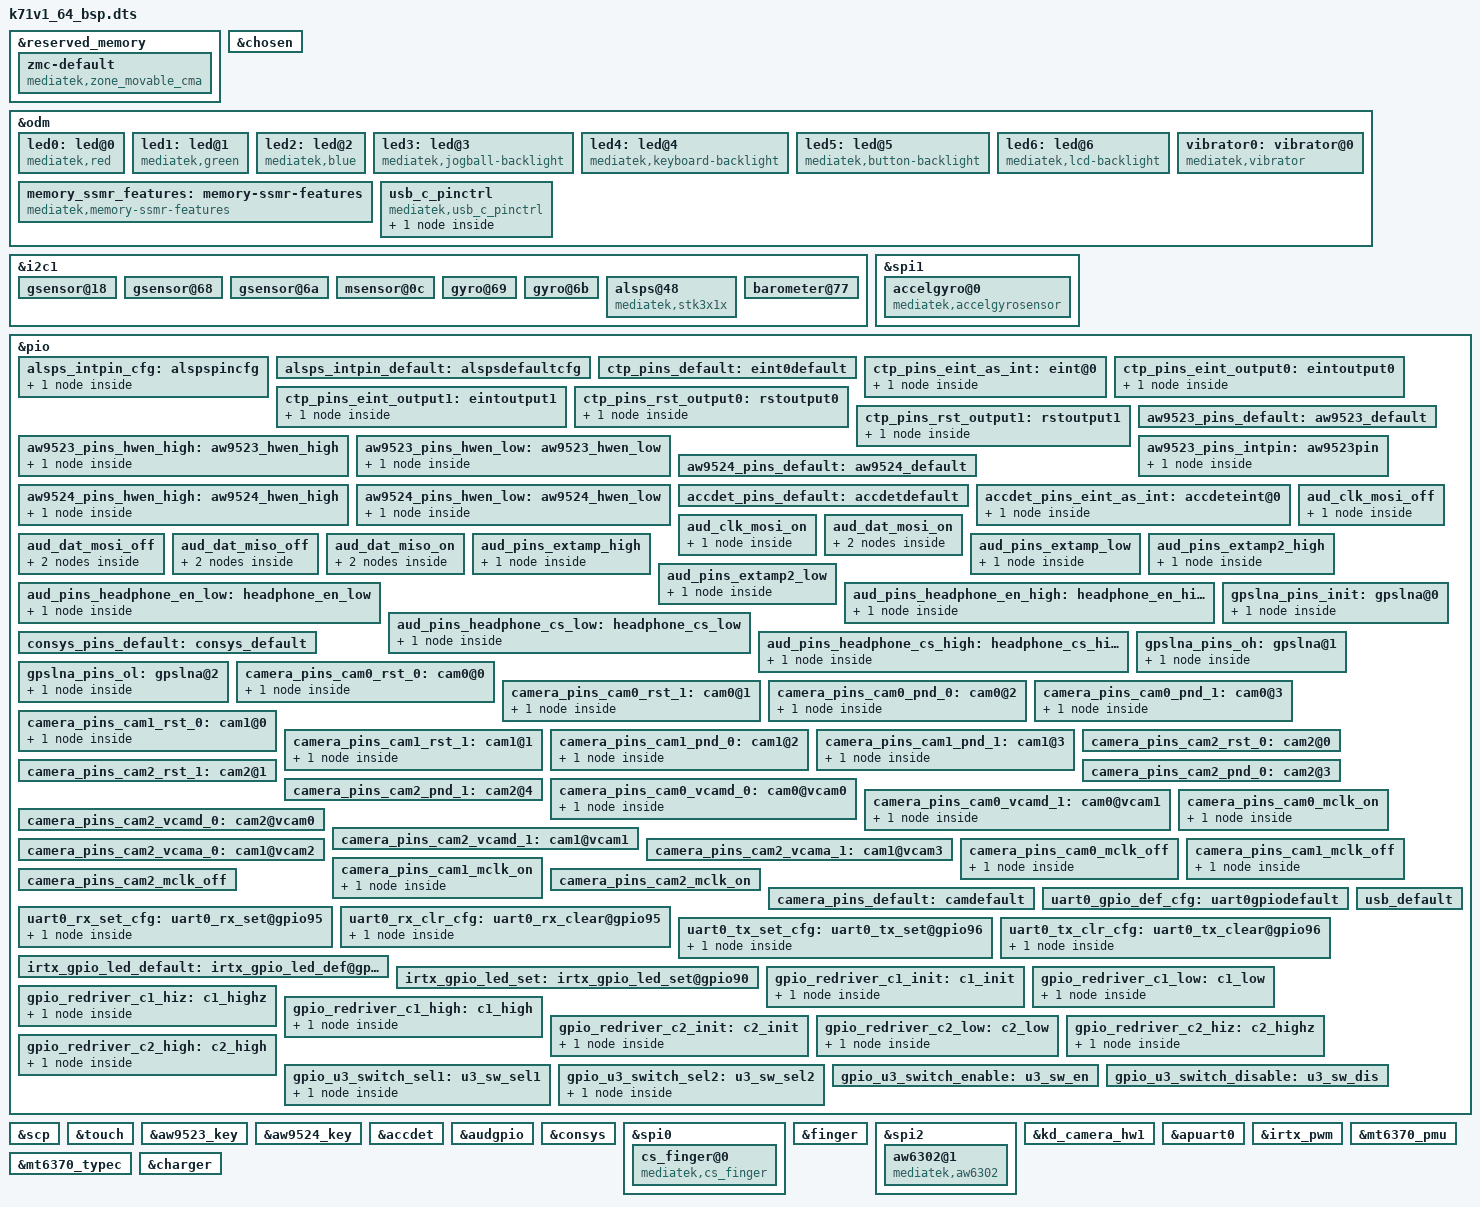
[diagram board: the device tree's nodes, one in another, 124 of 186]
/dts-v1/;
/plugin/;
#include <dt-bindings/interrupt-controller/irq.h>
#include <dt-bindings/interrupt-controller/arm-gic.h>
#include <dt-bindings/pinctrl/mt6771-pinfunc.h>

&reserved_memory {
	#address-cells = <2>;
	#size-cells = <2>;
	ranges;

	zmc-default {
		compatible = "mediatek,zone_movable_cma";
		size = <0 0xffc00000>;
		alignment = <0 0x10000000>;
		alloc-ranges = <0 0xc0000000 1 0x00000000>;
	};
};

/* chosen */
&chosen {
	/* fpga may has no lk, we need to specify display info here */
	/* fb buffer is reserved using this dts by memory node above */

	atag,videolfb-fb_base_l = <0x5e605000>;
	atag,videolfb-fb_base_h = <0x0>;
	atag,videolfb-islcmfound = <1>;
	atag,videolfb-islcm_inited = <0>;
	atag,videolfb-fps= <6000>;
	atag,videolfb-vramSize= <0x017bb000>;
	atag,videolfb-lcmname= "nt35595_fhd_dsi_cmd_truly_nt50358_drv";
};

&odm {
	led0:led@0 {
		compatible = "mediatek,red";
		led_mode = <0>;
		data = <1>;
		pwm_config = <0 0 0 0 0>;
	};
	led1:led@1 {
		compatible = "mediatek,green";
		led_mode = <0>;
		data = <1>;
		pwm_config = <0 0 0 0 0>;
	};
	led2:led@2 {
		compatible = "mediatek,blue";
		led_mode = <0>;
		data = <1>;
		pwm_config = <0 0 0 0 0>;
	};
	led3:led@3 {
		compatible = "mediatek,jogball-backlight";
		led_mode = <0>;
		data = <1>;
		pwm_config = <0 0 0 0 0>;
	};
	led4:led@4 {
		compatible = "mediatek,keyboard-backlight";
		led_mode = <0>;
		data = <1>;
		pwm_config = <0 0 0 0 0>;
	};
	led5:led@5 {
		compatible = "mediatek,button-backlight";
		led_mode = <0>;
		data = <1>;
		pwm_config = <0 0 0 0 0>;
	};
	led6:led@6 {
		compatible = "mediatek,lcd-backlight";
		led_mode = <5>;
		data = <1>;
		pwm_config = <0 1 0 0 0>;
	};
	vibrator0:vibrator@0 {
		compatible = "mediatek,vibrator";
		vib_timer = <25>;
		vib_limit = <9>;
		vib_vol= <9>;
	};
	memory_ssmr_features: memory-ssmr-features {
		compatible = "mediatek,memory-ssmr-features";
		svp-size = <0 0>;
		iris-recognition-size = <0 0>;
		2d_fr-size = <0 0>;
		tui-size = <0 0>;
		wfd-size = <0 0>;
		prot-sharedmem-size = <0 0>;
	};
	usb_c_pinctrl:usb_c_pinctrl {
		compatible = "mediatek,usb_c_pinctrl";
	};
};

&i2c1 {
/*  start sensor */
	gsensor@18 {
		/**STK8BA53**/
		i2c_num	= <1>;
		direction = <5>;
		power_id = <0xffff>;
		power_vol = <0>;
		firlen = <1>;
		is_batch_supported = <0>;
	};
	gsensor@68 {
		/**bmi160**/
		i2c_num	= <1>;
		direction = <5>;
		power_id = <0xffff>;
		power_vol = <0>;
		firlen = <16>;
		is_batch_supported = <1>;
	};
	gsensor@6a {
		/**lsm6ds3hg**/
		i2c_num	= <1>;
		direction = <4>;
		power_id = <0xffff>;
		power_vol = <0>;
		firlen = <16>;
		is_batch_supported = <1>;
	};
	msensor@0c {
		i2c_num = <1>;
		i2c_addr = <0x0c 0 0 0>;
		direction = <2>;
		power_id = <0xffff>;
		power_vol = <0>;
		is_batch_supported = <0>;
	};

	gyro@69 {
		i2c_num = <1>;
		i2c_addr = <0x69 0 0 0>;
		direction = <5>;
		power_id = <0xffff>;
		power_vol = <0>;
		firlen = <0>;
		is_batch_supported = <0>;
	};
	gyro@6b {
		i2c_num = <1>;
		i2c_addr = <0x6B 0 0 0>;
		direction = <4>;
		power_id = <0xffff>;
		power_vol = <0>;
		firlen = <0>;
		is_batch_supported = <0>;
	};
	alsps@48 {
		compatible = "mediatek,stk3x1x";
		pinctrl-names = "pin_default", "pin_cfg";
		pinctrl-0 = <&alsps_intpin_default>;
		pinctrl-1 = <&alsps_intpin_cfg>;
		status = "okay";
		/* customization */
		i2c_num = <1>;
		i2c_addr = <0x48 0 0 0>;
		polling_mode_ps = <0>;
		polling_mode_als = <1>;
		/*power_id = <0xffff>;*/
		/*power_vol = <0>;*/
		als_level  = <10  20 36 59 80 120 180 260 450 845 1136 1545 2364 4655 6982>;
		als_value  = <0 10 40 65 90 145 225 300 550 930 1250 1700 2600 5120 7680 10240>;
		state_val = <0x0>;              /* disable all */
		psctrl_val = <0x31>;            /* ps_persistance=4, ps_gain=64X, PS_IT=0.37ms */
		alsctrl_val = <0x38>;           /* als_persistance=1, als_gain=64X, ALS_IT=50ms */
		ledctrl_val = <0xFF>;   /* 100mA IRDR, 64/64 LED duty */
		wait_val = <0x7>;               /* 50 ms */
		ps_high_thd_val = <1700>;
		ps_low_thd_val = <1500>;
		ps_threshold_high		=  <30>;
		ps_threshold_low		=  <21>;
		is_batch_supported_ps = <0>;
		is_batch_supported_als = <0>;
	};

	barometer@77 {
		i2c_num = <1>;
		i2c_addr = <0x77 0 0 0>;
		direction = <0>;
		power_id = <0xffff>;
		power_vol = <0>;
		firlen = <32>;
		is_batch_supported = <0>;
	};
/* end sensor */
};

&spi1 {
       accelgyro@0 {
               /**bmi160**/
               compatible = "mediatek,accelgyrosensor";
		reg = <0>;
		spi-max-frequency = <8000000>;
		netlink-event = <30>;
		status = "okay";
               direction = <4>;
               power_id = <0xffff>;
               power_vol = <0>;
               firlen = <16>;
               is_batch_supported = <0>;
       };
};

/* sensor gpio standization */
&pio {
	alsps_intpin_cfg: alspspincfg {

		pins_cmd_dat {
			pins = <PINMUX_GPIO6__FUNC_GPIO6>;
			slew-rate = <0>;
			bias-pull-up = <00>;
		};
	};

	alsps_intpin_default: alspsdefaultcfg {

	};
};
/* sensor end */

&scp {
	core_1 = "enable";
	scp_sramSize = <0x00080000>;     /* scp_A_sram_size */
};

/* TOUCH start */
&touch {
	tpd-resolution = <1080 1920>;
	use-tpd-button = <0>;
	tpd-key-num = <3>;
	tpd-key-local= <139 172 158 0>;
	tpd-key-dim-local = <90 883 100 40 230 883 100 40 370 883 100 40 0 0 0 0>;
	tpd-max-touch-num = <5>;
	tpd-filter-enable = <1>;
	tpd-filter-pixel-density = <146>;
	tpd-filter-custom-prameters = <0 0 0 0 0 0 0 0 0 0 0 0>;
	tpd-filter-custom-speed = <0 0 0>;
	pinctrl-names = "default", "state_eint_as_int", "state_eint_output0", "state_eint_output1",
		"state_rst_output0", "state_rst_output1";
	pinctrl-0 = <&ctp_pins_default>;
	pinctrl-1 = <&ctp_pins_eint_as_int>;
	pinctrl-2 = <&ctp_pins_eint_output0>;
	pinctrl-3 = <&ctp_pins_eint_output1>;
	pinctrl-4 = <&ctp_pins_rst_output0>;
	pinctrl-5 = <&ctp_pins_rst_output1>;
	status = "okay";
};
&pio {
	ctp_pins_default: eint0default {
	};
	ctp_pins_eint_as_int: eint@0 {
		pins_cmd_dat {
			pins = <PINMUX_GPIO9__FUNC_GPIO9>;
			slew-rate = <0>;
			bias-disable;
		};
	};
	ctp_pins_eint_output0: eintoutput0 {
		pins_cmd_dat {
			pins = <PINMUX_GPIO9__FUNC_GPIO9>;
			slew-rate = <1>;
			output-low;
		};
	};
	ctp_pins_eint_output1: eintoutput1 {
		pins_cmd_dat {
			pins = <PINMUX_GPIO9__FUNC_GPIO9>;
			slew-rate = <1>;
			output-high;
		};
	};
	ctp_pins_rst_output0: rstoutput0 {
		pins_cmd_dat {
			pins = <PINMUX_GPIO156__FUNC_GPIO156>;
			slew-rate = <1>;
			output-low;
		};
	};
	ctp_pins_rst_output1: rstoutput1 {
		pins_cmd_dat {
			pins = <PINMUX_GPIO156__FUNC_GPIO156>;
			slew-rate = <1>; 
			output-high;
		}; 
	};
};
/* TOUCH end */

&aw9523_key {
	pinctrl-names = "default","aw9523_shdn_high","aw9523_shdn_low","aw9523_int_pin";
	pinctrl-0 = <&aw9523_pins_default>;
	pinctrl-1 = <&aw9523_pins_hwen_high>;
	pinctrl-2 = <&aw9523_pins_hwen_low>;
	pinctrl-3 = <&aw9523_pins_intpin>;
	status = "okay";
};
&pio {
	aw9523_pins_default: aw9523_default {
	};
	aw9523_pins_hwen_high: aw9523_hwen_high {
	    pins_cmd_dat {
			pins = <PINMUX_GPIO175__FUNC_GPIO175>;
			slew-rate = <1>;
			output-high;
		};
	};
	aw9523_pins_hwen_low: aw9523_hwen_low {
	    pins_cmd_dat {
			pins = <PINMUX_GPIO175__FUNC_GPIO175>;
			slew-rate = <1>;
			output-low;
		};
	};
    aw9523_pins_intpin: aw9523pin{
        pins_cmd_dat {
            pins = <PINMUX_GPIO12__FUNC_GPIO12>;
            slew-rate = <0>;
            bias-pull-up = <00>;
        };
    };
};
&aw9524_key {
	pinctrl-names = "default","aw9524_shdn_high","aw9524_shdn_low";
	pinctrl-0 = <&aw9524_pins_default>;
	pinctrl-1 = <&aw9524_pins_hwen_high>;
	pinctrl-2 = <&aw9524_pins_hwen_low>;
	status = "okay";
};
&pio {
	aw9524_pins_default: aw9524_default {
	};
	aw9524_pins_hwen_high: aw9524_hwen_high {
	    pins_cmd_dat {
			pins = <PINMUX_GPIO109__FUNC_GPIO109>;
			slew-rate = <1>;
			output-high;
		};
	};
	aw9524_pins_hwen_low: aw9524_hwen_low {
	    pins_cmd_dat {
			pins = <PINMUX_GPIO109__FUNC_GPIO109>;
			slew-rate = <1>;
			output-low;
		};
	};
};

/* accdet start */
&accdet {
	/* accdet micbias voltage: 0x07,2.7v;0x05,2.5v;0x02,1.9v */
	accdet-mic-vol = <6>;
	headset-mode-setting = <0x500 0x500 1 0x1f0 0x800 0x800 0x20 0x44>;
	accdet-plugout-debounce = <1>;
	/*1:ACC mode, 2:low cost without in bias, 6:low cost with in bias*/
	accdet-mic-mode = <1>;
	/* eint_level_trigger: 8,LEVEL_LOW(default);4,LEVEL_HIGH;others,LEVEL_LOW */
	headset-eint-level-pol = <8>;
	/*0--MD_MAX--UP_MAX--DW_MAX*/
	headset-three-key-threshold = <0 80 220 400>;
	headset-three-key-threshold-CDD = <0 121 192 600>;
	/*0--MD_MAX--VOICE_MAX--UP_MAX--DW_MAX*/
	headset-four-key-threshold = <0 58 121 192 400>;
	/*moisture external resister ohm*/
	moisture-external-r = <2000000>;
	/*moisture internal resister ohm*/
	moisture-internal-r = <47000>;
	/*moisture of water resister ohm*/
	moisture-water-r = <10000>;
	/* ACCDET GPIO standardization ACC mode no use */
	pinctrl-names = "default", "state_eint_as_int";
	pinctrl-0 = <&accdet_pins_default>;
	pinctrl-1 = <&accdet_pins_eint_as_int>;
	status = "okay";
};
&pio {
	accdet_pins_default: accdetdefault {
	};
	accdet_pins_eint_as_int: accdeteint@0 {
		pins_cmd_dat {
			/*pins = <PINMUX_GPIO7__FUNC_GPIO7>;*/
			slew-rate = <0>;
			bias-disable;
		};
	};
};
/* accdet end */

/* AUDIO GPIO standardization */
&audgpio {
	pinctrl-names = "aud_clk_mosi_off",
			"aud_clk_mosi_on",
			"aud_dat_mosi_off",
			"aud_dat_mosi_on",
			"aud_dat_miso_off",
			"aud_dat_miso_on",
			"extamp-pullhigh",
			"extamp-pulllow",
			"extamp2-pullhigh",
			"extamp2-pulllow",
			"headphone_en_high",
			"headphone_en_low",
			"headphone_cs_high",
			"headphone_cs_low";
	pinctrl-0 = <&aud_clk_mosi_off>;
	pinctrl-1 = <&aud_clk_mosi_on>;
	pinctrl-2 = <&aud_dat_mosi_off>;
	pinctrl-3 = <&aud_dat_mosi_on>;
	pinctrl-4 = <&aud_dat_miso_off>;
	pinctrl-5 = <&aud_dat_miso_on>;
	pinctrl-6 = <&aud_pins_extamp_high>;
	pinctrl-7 = <&aud_pins_extamp_low>;
	pinctrl-8 = <&aud_pins_extamp2_high>;
	pinctrl-9 = <&aud_pins_extamp2_low>;
	pinctrl-10 = <&aud_pins_headphone_en_high>;
	pinctrl-11 = <&aud_pins_headphone_en_low>;
	pinctrl-12 = <&aud_pins_headphone_cs_high>;
	pinctrl-13 = <&aud_pins_headphone_cs_low>;	
	status = "okay";
};

&pio {
	aud_clk_mosi_off: aud_clk_mosi_off {
		pins_cmd0_dat {
			pins = <PINMUX_GPIO136__FUNC_GPIO136>;
		};
	};

	aud_clk_mosi_on: aud_clk_mosi_on {
		pins_cmd0_dat {
			pins = <PINMUX_GPIO136__FUNC_AUD_CLK_MOSI>;
		};
	};

	aud_dat_mosi_off: aud_dat_mosi_off {
		pins_cmd1_dat {
			pins = <PINMUX_GPIO138__FUNC_GPIO138>;
		};
		pins_cmd2_dat {
			pins = <PINMUX_GPIO139__FUNC_GPIO139>;
		};
	};

	aud_dat_mosi_on: aud_dat_mosi_on {
		pins_cmd1_dat {
			pins = <PINMUX_GPIO138__FUNC_AUD_DAT_MOSI0>;
		};
		pins_cmd2_dat {
			pins = <PINMUX_GPIO139__FUNC_AUD_DAT_MOSI1>;
		};
	};

	aud_dat_miso_off: aud_dat_miso_off {
		pins_cmd1_dat {
			pins = <PINMUX_GPIO142__FUNC_GPIO142>;
		};
		pins_cmd2_dat {
			pins = <PINMUX_GPIO143__FUNC_GPIO143>;
		};
	};

	aud_dat_miso_on: aud_dat_miso_on {
		pins_cmd1_dat {
			pins = <PINMUX_GPIO142__FUNC_AUD_DAT_MISO0>;
		};
		pins_cmd2_dat {
			pins = <PINMUX_GPIO143__FUNC_AUD_DAT_MISO1>;
		};
	};
	aud_pins_extamp_high: aud_pins_extamp_high {
		pins_cmd0_dat {
			pins = <PINMUX_GPIO153__FUNC_GPIO153>;
			slew-rate = <1>;
			output-high;
		};
	};

	aud_pins_extamp_low: aud_pins_extamp_low {
		pins_cmd0_dat {
			pins = <PINMUX_GPIO153__FUNC_GPIO153>;
			slew-rate = <1>;
			output-low;
		};
	};
	aud_pins_extamp2_high: aud_pins_extamp2_high {
		pins_cmd1_dat {
			pins = <PINMUX_GPIO111__FUNC_GPIO111>;
			slew-rate = <1>;
			output-high;
		};
	};

	aud_pins_extamp2_low: aud_pins_extamp2_low {
		pins_cmd2_dat {
			pins = <PINMUX_GPIO111__FUNC_GPIO111>;
			slew-rate = <1>;
			output-low;
		};
	};
	aud_pins_headphone_en_low: headphone_en_low {
		pins_cmd_dat {
			pins = <PINMUX_GPIO108__FUNC_GPIO108>;
			slew-rate = <1>;
			output-low;
		};
	};

	aud_pins_headphone_en_high: headphone_en_high {
		pins_cmd_dat {
			pins = <PINMUX_GPIO108__FUNC_GPIO108>;
			slew-rate = <1>;
			output-high;
		};
	};
	aud_pins_headphone_cs_low: headphone_cs_low {
		pins_cmd_dat {
			pins = <PINMUX_GPIO107__FUNC_GPIO107>;
			slew-rate = <1>;
			output-low;
		};
	};

	aud_pins_headphone_cs_high: headphone_cs_high {
		pins_cmd_dat {
			pins = <PINMUX_GPIO107__FUNC_GPIO107>;
			slew-rate = <1>;
			output-high;
		};
	};		
};
/* AUDIO end */

/* CONSYS GPIO standardization */
&pio {
	consys_pins_default: consys_default {
	};
	gpslna_pins_init: gpslna@0 {
		pins_cmd_dat {
			pins = <PINMUX_GPIO155__FUNC_GPIO155>;
			slew-rate = <0>;
			bias-disable;
			output-low;
		};
	};
	gpslna_pins_oh: gpslna@1 {
		pins_cmd_dat {
			pins = <PINMUX_GPIO155__FUNC_GPIO155>;
			slew-rate = <1>;
			output-high;
		};
	};
	gpslna_pins_ol: gpslna@2 {
		pins_cmd_dat {
			pins = <PINMUX_GPIO155__FUNC_GPIO155>;
			slew-rate = <1>;
			output-low;
		};
	};
};
&consys {
	pinctrl-names = "default", "gps_lna_state_init", "gps_lna_state_oh", "gps_lna_state_ol";
	pinctrl-0 = <&consys_pins_default>;
	pinctrl-1 = <&gpslna_pins_init>;
	pinctrl-2 = <&gpslna_pins_oh>;
	pinctrl-3 = <&gpslna_pins_ol>;
	status = "okay";
};
/* CONSYS end */
/*CS finger*/
&spi0 {
       #address-cells = <1>;
       #size-cells = <0>;
       cs_finger@0 {
               compatible = "mediatek,cs_finger";
               reg = <0>;
               spi-max-frequency = <1500000>;
               status = "okay";
       };
};

&finger{
    interrupt-parent = <&pio>;
    interrupts = <5 IRQ_TYPE_EDGE_RISING 5 0>;
    debounce = <256000>;
    status = "okay";
};
#include "ChipSailing_pin.dtsi"

&spi2 {
       #address-cells = <1>;
       #size-cells = <0>;
       aw6302@1 {
               compatible = "mediatek,aw6302";
               reg = <0>;
               spi-max-frequency = <1500000>;
               status = "okay";
       };
};

/* CAMERA GPIO standardization */
&pio {
	camera_pins_cam0_rst_0: cam0@0 {
		pins_cmd_dat {
			pins = <PINMUX_GPIO101__FUNC_GPIO101>;
			slew-rate = <1>; /*direction 0:in, 1:out*/
			output-low;/*direction out used only. output_low or high*/
		};
	};
	camera_pins_cam0_rst_1: cam0@1 {
		pins_cmd_dat {
			pins = <PINMUX_GPIO101__FUNC_GPIO101>;
			slew-rate = <1>;
			output-high;
		};
	};
	camera_pins_cam0_pnd_0: cam0@2 {
		pins_cmd_dat {
			pins = <PINMUX_GPIO97__FUNC_GPIO97>;
			slew-rate = <1>;
			output-low;
		};
	};
	camera_pins_cam0_pnd_1: cam0@3 {
		pins_cmd_dat {
			pins = <PINMUX_GPIO97__FUNC_GPIO97>;
			slew-rate = <1>;
			output-high;
		};
	};
	camera_pins_cam1_rst_0: cam1@0 {
		pins_cmd_dat {
			pins = <PINMUX_GPIO102__FUNC_GPIO102>;
			slew-rate = <1>; /*direction 0:in, 1:out*/
			output-low;/*direction out used only. output_low or high*/
		};
	};
	camera_pins_cam1_rst_1: cam1@1 {
		pins_cmd_dat {
			pins = <PINMUX_GPIO102__FUNC_GPIO102>;
			slew-rate = <1>;
			output-high;
		};
	};
	camera_pins_cam1_pnd_0: cam1@2 {
		pins_cmd_dat {
			pins = <PINMUX_GPIO98__FUNC_GPIO98>;
			slew-rate = <1>;
			output-low;
		};
	};
	camera_pins_cam1_pnd_1: cam1@3 {
		pins_cmd_dat {
			pins = <PINMUX_GPIO98__FUNC_GPIO98>;
			slew-rate = <1>;
			output-high;
		};
	};
	camera_pins_cam2_rst_0: cam2@0 {
		//pins_cmd_dat {
			//pins = <PINMUX_GPIO109__FUNC_GPIO109>;
			//slew-rate = <1>;
			//output-low;
		//};
	};
	camera_pins_cam2_rst_1: cam2@1 {
		//pins_cmd_dat {
			//pins = <PINMUX_GPIO109__FUNC_GPIO109>;
			//slew-rate = <1>;
			//output-high;
		//};
	};
	camera_pins_cam2_pnd_0: cam2@3 {
		//pins_cmd_dat {
			//pins = <PINMUX_GPIO107__FUNC_GPIO107>;
			//slew-rate = <1>;
			//output-low;
		//};
	};
	camera_pins_cam2_pnd_1: cam2@4 {
		//pins_cmd_dat {
			//pins = <PINMUX_GPIO107__FUNC_GPIO107>;
			//slew-rate = <1>;
			//output-high;
		//};
	};
	camera_pins_cam0_vcamd_0: cam0@vcam0 {
		pins_cmd_dat {
			pins = <PINMUX_GPIO91__FUNC_GPIO91>;
			slew-rate = <1>;
			output-low;
		};
	};
	camera_pins_cam0_vcamd_1: cam0@vcam1 {
		pins_cmd_dat {
			pins = <PINMUX_GPIO91__FUNC_GPIO91>;
			slew-rate = <1>;
			output-high;
		};
	};
	camera_pins_cam2_vcamd_0: cam2@vcam0 {
		//pins_cmd_dat {
			//pins = <PINMUX_GPIO169__FUNC_GPIO169>;
			//slew-rate = <1>;
			//output-low;
		//};
	};
	camera_pins_cam2_vcamd_1: cam1@vcam1 {
		//pins_cmd_dat {
			//pins = <PINMUX_GPIO169__FUNC_GPIO169>;
			//slew-rate = <1>;
			//output-high;
		//};
	};
	camera_pins_cam2_vcama_0: cam1@vcam2 {
		//pins_cmd_dat {
			//pins = <PINMUX_GPIO169__FUNC_GPIO169>;
			//slew-rate = <1>;
			//output-low;
		//};
	};
	camera_pins_cam2_vcama_1: cam1@vcam3 {
		//pins_cmd_dat {
			//pins = <PINMUX_GPIO169__FUNC_GPIO169>;
			//slew-rate = <1>;
			//output-high;
		//};
	};
	camera_pins_cam0_mclk_on: camera_pins_cam0_mclk_on {
		pins_cmd_dat {
			pins = <PINMUX_GPIO99__FUNC_CMMCLK0>;
		};
	};
	camera_pins_cam0_mclk_off: camera_pins_cam0_mclk_off {
		pins_cmd_dat {
			pins = <PINMUX_GPIO99__FUNC_GPIO99>;
		};
	};
	camera_pins_cam1_mclk_off: camera_pins_cam1_mclk_off {
		pins_cmd_dat {
			pins = <PINMUX_GPIO100__FUNC_GPIO100>;
		};
	};
	camera_pins_cam1_mclk_on: camera_pins_cam1_mclk_on {
		pins_cmd_dat {
			pins = <PINMUX_GPIO100__FUNC_CMMCLK1>;
		};
	};
	camera_pins_cam2_mclk_off: camera_pins_cam2_mclk_off {
		//pins_cmd_dat {
			//pins = <PINMUX_GPIO108__FUNC_GPIO108>;
		//};
	};
	camera_pins_cam2_mclk_on: camera_pins_cam2_mclk_on {
		//pins_cmd_dat {
			//pins = <PINMUX_GPIO108__FUNC_CMMCLK2>;
		//};
	};
	camera_pins_default: camdefault {
	};
};
&kd_camera_hw1 {
	pinctrl-names = "default",
			"cam0_rst0", "cam0_rst1",
			"cam0_pnd0", "cam0_pnd1",
			"cam1_rst0", "cam1_rst1",
			"cam1_pnd0", "cam1_pnd1",
			"cam2_rst0", "cam2_rst1",
			"cam2_pnd0", "cam2_pnd1",
			"cam_ldo_vcamd_0", "cam_ldo_vcamd_1",
			"cam_ldo_main2_vcamd_0", "cam_ldo_main2_vcamd_1",
			"cam_ldo_main2_vcama_0", "cam_ldo_main2_vcama_1",
			"cam0_mclk_off", "cam0_mclk_on",
			"cam1_mclk_off", "cam1_mclk_on",
			"cam2_mclk_off", "cam2_mclk_on";
	pinctrl-0 = <&camera_pins_default>;
	pinctrl-1 = <&camera_pins_cam0_rst_0>;
	pinctrl-2 = <&camera_pins_cam0_rst_1>;
	pinctrl-3 = <&camera_pins_cam0_pnd_0>;
	pinctrl-4 = <&camera_pins_cam0_pnd_1>;
	pinctrl-5 = <&camera_pins_cam1_rst_0>;
	pinctrl-6 = <&camera_pins_cam1_rst_1>;
	pinctrl-7 = <&camera_pins_cam1_pnd_0>;
	pinctrl-8 = <&camera_pins_cam1_pnd_1>;
	pinctrl-9 = <&camera_pins_cam2_rst_0>;
	pinctrl-10 = <&camera_pins_cam2_rst_1>;
	pinctrl-11 = <&camera_pins_cam2_pnd_0>;
	pinctrl-12 = <&camera_pins_cam2_pnd_1>;
	pinctrl-13 = <&camera_pins_cam0_vcamd_0>;
	pinctrl-14 = <&camera_pins_cam0_vcamd_1>;
	pinctrl-15 = <&camera_pins_cam2_vcamd_0>;
	pinctrl-16 = <&camera_pins_cam2_vcamd_1>;
	pinctrl-17 = <&camera_pins_cam2_vcama_0>;
	pinctrl-18 = <&camera_pins_cam2_vcama_1>;
	pinctrl-19 = <&camera_pins_cam0_mclk_off>;
	pinctrl-20 = <&camera_pins_cam0_mclk_on>;
	pinctrl-21 = <&camera_pins_cam1_mclk_off>;
	pinctrl-22 = <&camera_pins_cam1_mclk_on>;
	pinctrl-23 = <&camera_pins_cam2_mclk_off>;
	pinctrl-24 = <&camera_pins_cam2_mclk_on>;

	status = "okay";
};

/* UART GPIO */
&apuart0 {
	pinctrl-names = "uart0_gpio_default",
			"uart0_rx_set",
			"uart0_rx_clear",
			"uart0_tx_set",
			"uart0_tx_clear";
	pinctrl-0 = <&uart0_gpio_def_cfg>;
	pinctrl-1 = <&uart0_rx_set_cfg>;
	pinctrl-2 = <&uart0_rx_clr_cfg>;
	pinctrl-3 = <&uart0_tx_set_cfg>;
	pinctrl-4 = <&uart0_tx_clr_cfg>;
	status = "okay";
};

&pio {
	/* UART GPIO Settings - Start */
	/* UART0: rx set, rx clear, tx clear, tx clear*/
	uart0_gpio_def_cfg:uart0gpiodefault {

	};
	uart0_rx_set_cfg:uart0_rx_set@gpio95 {
		pins_cmd_dat {
			pins = <PINMUX_GPIO95__FUNC_URXD0>;
		};
	};
	uart0_rx_clr_cfg:uart0_rx_clear@gpio95 {
		pins_cmd_dat {
			pins = <PINMUX_GPIO95__FUNC_GPIO95>;
			slew-rate = <1>;
			output-high;
		};
	};
	uart0_tx_set_cfg:uart0_tx_set@gpio96 {
		pins_cmd_dat {
			pins = <PINMUX_GPIO96__FUNC_UTXD0>;
		};
	};
	uart0_tx_clr_cfg:uart0_tx_clear@gpio96 {
		pins_cmd_dat {
			pins = <PINMUX_GPIO96__FUNC_GPIO96>;
			slew-rate = <1>;
			output-high;
		};
	};
};/* UART GPIO end */

/* IRTX GPIO Start */
&irtx_pwm {
	pinctrl-names = "irtx_gpio_led_default", "irtx_gpio_led_set";
	pinctrl-0 = <&irtx_gpio_led_default>;
	pinctrl-1 = <&irtx_gpio_led_set>;
	status = "okay";
};
&pio {
	/* IRTX GPIO Settings -Start */
	/* default: GPIO0, output, high */
	irtx_gpio_led_default:irtx_gpio_led_def@gpio90 {
		//pins_cmd_dat {
			//pins = <PINMUX_GPIO90__FUNC_GPIO90>;
			//slew-rate = <1>;
			//bias-disable;
			//output-low;
			//input-schmitt-enable = <0>;
		//};
	};

	irtx_gpio_led_set:irtx_gpio_led_set@gpio90 {
		//pins_cmd_dat {
			//pins = <PINMUX_GPIO90__FUNC_PWM_A>;
			//slew-rate = <1>;
			//output-high;
		//};
	};
}; /* IRTX GPIO Settings -End */

&mt6370_pmu {
	mt6370,intr_gpio_num = <10>; /* direct defined GPIO num */
	mt6370,intr_gpio = <&pio 10 0x0>;
};

&mt6370_typec {
	mt6370pd,intr_gpio_num = <41>; /* direct defined GPIO num */
	mt6370pd,intr_gpio = <&pio 41 0x0>;
};

/* USB TYPEC GPIO start */
&pio {
	usb_default: usb_default {
	};

	gpio_redriver_c1_init: c1_init {
		pins_cmd_dat {
			pins = <PINMUX_GPIO18__FUNC_GPIO18>;
			slew-rate = <1>;
			output-low;
		};
	};

	gpio_redriver_c1_low: c1_low {
		pins_cmd_dat {
			pins = <PINMUX_GPIO18__FUNC_GPIO18>;
			slew-rate = <1>;
			output-low;
		};
	};

	gpio_redriver_c1_hiz: c1_highz {
		pins_cmd_dat {
			pins = <PINMUX_GPIO18__FUNC_GPIO18>;
			slew-rate= <0>;
			bias-disable;
		};
	};

	gpio_redriver_c1_high: c1_high {
		pins_cmd_dat {
			pins = <PINMUX_GPIO18__FUNC_GPIO18>;
			slew-rate = <1>;
			output-high;
		};
	};

	gpio_redriver_c2_init: c2_init {
		pins_cmd_dat {
			pins = <PINMUX_GPIO17__FUNC_GPIO17>;
			slew-rate = <1>;
			output-low;
		};
	};

	gpio_redriver_c2_low: c2_low {
		pins_cmd_dat {
			pins = <PINMUX_GPIO17__FUNC_GPIO17>;
			slew-rate = <1>;
			output-low;
		};
	};

	gpio_redriver_c2_hiz: c2_highz {
		pins_cmd_dat {
			pins = <PINMUX_GPIO17__FUNC_GPIO17>;
			slew-rate= <0>;
			bias-disable;
		};
	};

	gpio_redriver_c2_high: c2_high {
		pins_cmd_dat {
			pins = <PINMUX_GPIO17__FUNC_GPIO17>;
			slew-rate = <1>;
			output-high;
		};
	};

	gpio_u3_switch_sel1: u3_sw_sel1 {
		pins_cmd_dat {
			pins = <PINMUX_GPIO177__FUNC_GPIO177>;
			slew-rate = <1>;
			output-low;
		};
	};

	gpio_u3_switch_sel2: u3_sw_sel2 {
		pins_cmd_dat {
			pins = <PINMUX_GPIO177__FUNC_GPIO177>;
			slew-rate = <1>;
			output-high;
		};
	};

	gpio_u3_switch_enable: u3_sw_en {
	};

	gpio_u3_switch_disable: u3_sw_dis {
	};
};

&usb_c_pinctrl {
	pinctrl-names = "usb_default",
		"redriver_c1_init",
		"redriver_c1_low",
		"redriver_c1_hiz",
		"redriver_c1_high",
		"redriver_c2_init",
		"redriver_c2_low",
		"redriver_c2_hiz",
		"redriver_c2_high",
		"u3_switch_sel1",
		"u3_switch_sel2",
		"u3_switch_enable",
		"u3_switch_disable";

	pinctrl-0 = <&usb_default>;
	pinctrl-1 = <&gpio_redriver_c1_init>;
	pinctrl-2 = <&gpio_redriver_c1_low>;
	pinctrl-3 = <&gpio_redriver_c1_hiz>;
	pinctrl-4 = <&gpio_redriver_c1_high>;
	pinctrl-5 = <&gpio_redriver_c2_init>;
	pinctrl-6 = <&gpio_redriver_c2_low>;
	pinctrl-7 = <&gpio_redriver_c2_hiz>;
	pinctrl-8 = <&gpio_redriver_c2_high>;
	pinctrl-9 = <&gpio_u3_switch_sel1>;
	pinctrl-10 = <&gpio_u3_switch_sel2>;
	pinctrl-11 = <&gpio_u3_switch_enable>;
	pinctrl-12 = <&gpio_u3_switch_disable>;
	status = "okay";

	usb_switch-data {
		en_pin_num = <0>;
		en_pin_val = <0>; /*DISABLE=0 ENABLE=1*/
		sel_pin_num = <177>;
		sel_pin_val = <1>; /*CC1=1, CC2=2*/
		c1_pin_num = <18>;
		c1_pin_val = <2>; /*Low=0, HighZ=1, High=2*/
		c2_pin_num = <17>;
		c2_pin_val = <1>;
	};
};
/* USB TYPEC GPIO end */

&charger {
	algorithm_name = "SwitchCharging";
	chg1_ta_ac_charger_current = <2000000>;
	chg2_ta_ac_charger_current = <2000000>;
};



//&i2c6 {
//	rt9465@4b {
	//	compatible = "richtek,rt9465";
	//	reg = <0x4b>;
		//status = "okay";
	//	rt,en_gpio_num = <179>;
	//	rt,en_gpio = <&pio 179 0x0>;
	//	mt6306_en_pin = <1>;
	//	rt,intr_gpio_num = <9>; /* direct defined GPIO num */
	//	rt,intr_gpio = <&pio 9 0x0>;
//		interrupt-names = "wdtmri";
	//	charger_name = "secondary_chg";
//		ichg = <1500000>; /* uA */
	//	mivr = <4500000>; /* uV */
//		cv = <4550000>; /* uV */
	//	ieoc = <700000>; /* uA */
//		safety_timer = <12>; /* hour */
//		en_st; /* safety timer */
		/* en_te; */
//		en_wdt;
//	};
//};

#include <k71v1_64_bsp/cust.dtsi>
/*End of this file, DO NOT ADD ANYTHING HERE*/


